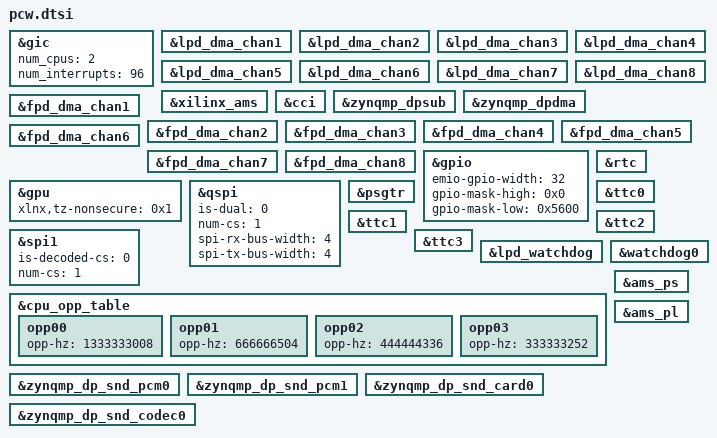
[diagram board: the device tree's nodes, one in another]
/*
 * CAUTION: This file is automatically generated by Xilinx.
 * Version: XSCT 2022.1
 * Today is: Tue Jan 27 16:07:11 2026
 */


&gic {
	num_cpus = <2>;
	num_interrupts = <96>;
};
&lpd_dma_chan1 {
	status = "okay";
};
&lpd_dma_chan2 {
	status = "okay";
};
&lpd_dma_chan3 {
	status = "okay";
};
&lpd_dma_chan4 {
	status = "okay";
};
&lpd_dma_chan5 {
	status = "okay";
};
&lpd_dma_chan6 {
	status = "okay";
};
&lpd_dma_chan7 {
	status = "okay";
};
&lpd_dma_chan8 {
	status = "okay";
};
&xilinx_ams {
	status = "okay";
};
&cci {
	status = "okay";
};
&zynqmp_dpsub {
	status = "okay";
};
&zynqmp_dpdma {
	status = "okay";
};
&fpd_dma_chan1 {
	status = "okay";
};
&fpd_dma_chan2 {
	status = "okay";
};
&fpd_dma_chan3 {
	status = "okay";
};
&fpd_dma_chan4 {
	status = "okay";
};
&fpd_dma_chan5 {
	status = "okay";
};
&fpd_dma_chan6 {
	status = "okay";
};
&fpd_dma_chan7 {
	status = "okay";
};
&fpd_dma_chan8 {
	status = "okay";
};
&gpio {
	emio-gpio-width = <32>;
	gpio-mask-high = <0x0>;
	gpio-mask-low = <0x5600>;
	status = "okay";
};
&gpu {
	status = "okay";
	xlnx,tz-nonsecure = <0x1>;
};
&qspi {
	is-dual = <0>;
	num-cs = <1>;
	spi-rx-bus-width = <4>;
	spi-tx-bus-width = <4>;
	status = "okay";
};
&rtc {
	status = "okay";
};
&psgtr {
	status = "okay";
};
&spi1 {
	is-decoded-cs = <0>;
	num-cs = <1>;
	status = "okay";
};
&ttc0 {
	status = "okay";
};
&ttc1 {
	status = "okay";
};
&ttc2 {
	status = "okay";
};
&ttc3 {
	status = "okay";
};
&lpd_watchdog {
	status = "okay";
};
&watchdog0 {
	status = "okay";
};
&cpu_opp_table {
	opp00 {
		opp-hz = /bits/ 64 <1333333008>;
	};
	opp01 {
		opp-hz = /bits/ 64 <666666504>;
	};
	opp02 {
		opp-hz = /bits/ 64 <444444336>;
	};
	opp03 {
		opp-hz = /bits/ 64 <333333252>;
	};
};
&ams_ps {
	status = "okay";
};
&ams_pl {
	status = "okay";
};
&zynqmp_dp_snd_pcm0 {
	status = "okay";
};
&zynqmp_dp_snd_pcm1 {
	status = "okay";
};
&zynqmp_dp_snd_card0 {
	status = "okay";
};
&zynqmp_dp_snd_codec0 {
	status = "okay";
};
